# M460 register map
File version: 1.0
Registers are 32-bit, read-write, reset 0x0 unless marked. A register's access mark holds for its fields unless they carry their own. Offsets are from the block's base; [hi:lo] are bit positions; {n}, {i} and the like mark numbered series; 'fields as' and 'values as' point back to an identical list.

## ACMP23 — ACMP Register Map
Base 0x400C9000
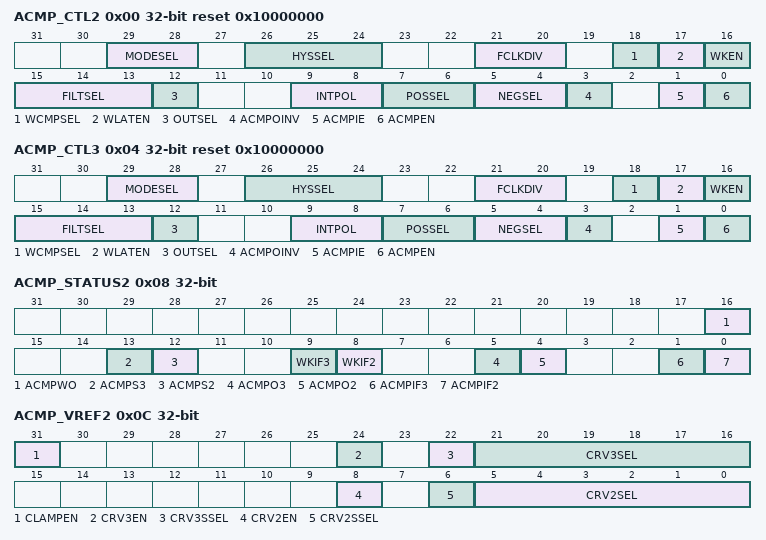
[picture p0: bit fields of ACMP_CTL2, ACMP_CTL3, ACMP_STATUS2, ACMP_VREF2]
0x00 ACMP_CTL2 reset 0x10000000 — Analog Comparator 2 Control Register
  [29:28] MODESEL — Comparator Power Mode Selection. Note: There is a setup time TSetup after comparator is enabled or MODESEL is changed. User should wait this TSetup to make comparator working normally, or user may get unstable comparator output value.
    0=Low power mode comparator AVDD current 1uA; 1=Low power mode comparator AVDD current 2uA; 2=Active mode comparator AVDD current 35uA; 3=Active mode comparator AVDD current 70uA
  [26:24] HYSSEL — Hysteresis Mode Selection
    0=Hysteresis is 0mV; 1=Hysteresis is 10mV; 2=Hysteresis is 20mV; 3=Hysteresis is 30mV; 4=Hysteresis is 40mV; 5=Hysteresis is 50mV
  [21:20] FCLKDIV — Comparator Output Filter Clock Divider
    0=Comparator output filter clock = PCLK; 1=Comparator output filter clock = PCLK/2; 2=Comparator output filter clock = PCLK/4
  [18] WCMPSEL — Window Compare Mode Selection
    0=Window Compare Mode Disabled; 1=Window Compare Mode Selected
  [17] WLATEN — Window Latch Mode Enable Bit
    0=Window Latch Mode Disabled; 1=Window Latch Mode Enabled
  [16] WKEN — Power-down Wake-up Enable Bit
    0=Wake-up function Disabled; 1=Wake-up function Enabled
  [15:13] FILTSEL — Comparator Output Filter Count Selection
    0=Filter function is Disabled; 1=ACMP2 output is sampled 1 consecutive PCLK; 2=ACMP2 output is sampled 2 consecutive PCLKs; 3=ACMP2 output is sampled 4 consecutive PCLKs; 4=ACMP2 output is sampled 8 consecutive PCLKs; 5=ACMP2 output is sampled 16 consecutive PCLKs; 6=ACMP2 output is sampled 32 consecutive PCLKs; 7=ACMP2 output is sampled 64 consecutive PCLKs
  [12] OUTSEL — Comparator Output Select
    0=Comparator 2 output to ACMP2_O pin is unfiltered comparator output; 1=Comparator 2 output to ACMP2_O pin is from filter output
  [9:8] INTPOL — Interrupt Condition Polarity Selection. ACMPIF2 will be set to 1 when comparator output edge condition is detected.
    0=Rising edge or falling edge; 1=Rising edge; 2=Falling edge
  [7:6] POSSEL — Comparator Positive Input Selection
    {v}=Input from ACMP2_P{v} (v=0..3)
  [5:4] NEGSEL — Comparator Negative Input Selection. Note: NEGSEL must select 0x1 in calibration mode.
    0=ACMP2_N pin; 1=Internal comparator reference voltage (CRV2); 2=Band-gap voltage; 3=DAC1 output
  [3] ACMPOINV — Comparator Output Inverse
    0=Comparator 2 output inverse Disabled; 1=Comparator 2 output inverse Enabled
  [1] ACMPIE — Comparator Interrupt Enable Bit
    0=Comparator 2 interrupt Disabled; 1=Comparator 2 interrupt Enabled. If WKEN (ACMP_CTL2[16]) is set to 1, the wake-up interrupt function will be enabled as well
  [0] ACMPEN — Comparator Enable Bit. Note: There is a setup time TSetup after comparator is enabled or MODESEL is changed. User should wait this TSetup to make comparator working normally, or user may get unstable comparator output value.
    0=Comparator 2 Disabled; 1=Comparator 2 Enabled
0x04 ACMP_CTL3 reset 0x10000000 — Analog Comparator 3 Control Register
  [29:28] MODESEL — Comparator Power Mode Selection. Note: There is a setup time TSetup after comparator is enabled or MODESEL is changed. User should wait this TSetup to make comparator working normally, or user may get unstable comparator output value.
    values as ACMP_CTL2.MODESEL
  [26:24] HYSSEL — Hysteresis Mode Selection
    values as ACMP_CTL2.HYSSEL
  [21:20] FCLKDIV — Comparator Output Filter Clock Divider
    values as ACMP_CTL2.FCLKDIV
  [18] WCMPSEL — Window Compare Mode Selection
    values as ACMP_CTL2.WCMPSEL
  [17] WLATEN — Window Latch Mode Enable Bit
    0=Window Latch Mode Disabled; 1=Window Latch Mode Enabled
  [16] WKEN — Power-down Wakeup Enable Bit
    0=Wake-up function Disabled; 1=Wake-up function Enabled
  [15:13] FILTSEL — Comparator Output Filter Count Selection
    0=Filter function is Disabled; 1=ACMP3 output is sampled 1 consecutive PCLK; 2=ACMP3 output is sampled 2 consecutive PCLKs; 3=ACMP3 output is sampled 4 consecutive PCLKs; 4=ACMP3 output is sampled 8 consecutive PCLKs; 5=ACMP3 output is sampled 16 consecutive PCLKs; 6=ACMP3 output is sampled 32 consecutive PCLKs; 7=ACMP3 output is sampled 64 consecutive PCLKs
  [12] OUTSEL — Comparator Output Select
    0=Comparator 3 output to ACMP3_O pin is unfiltered comparator output; 1=Comparator 3 output to ACMP3_O pin is from filter output
  [9:8] INTPOL — Interrupt Condition Polarity Selection. ACMPIF3 will be set to 1 when comparator output edge condition is detected.
    0=Rising edge or falling edge; 1=Rising edge; 2=Falling edge
  [7:6] POSSEL — Comparator Positive Input Selection
    {v}=Input from ACMP3_P{v} (v=0..3)
  [5:4] NEGSEL — Comparator Negative Input Selection. Note: NEGSEL must select 0x1 in calibration mode.
    0=ACMP3_N pin; 1=Internal comparator reference voltage (CRV3); 2=Band-gap voltage; 3=DAC1 output
  [3] ACMPOINV — Comparator Output Inverse Control
    0=Comparator 3 output inverse Disabled; 1=Comparator 3 output inverse Enabled
  [1] ACMPIE — Comparator Interrupt Enable Bit
    0=Comparator 3 interrupt Disabled; 1=Comparator 3 interrupt Enabled. If WKEN (ACMP_CTL1[16]) is set to 1, the wake-up interrupt function will be enabled as well
  [0] ACMPEN — Comparator Enable Bit. Note: There is a setup time TSetup after comparator is enabled or MODESEL is changed. User should wait this TSetup to make comparator working normally, or user may get unstable comparator output value.
    0=Comparator 3 Disabled; 1=Comparator 3 Enabled
0x08 ACMP_STATUS2 — Analog Comparator Status Register 2
  [16] ACMPWO — Comparator Window Output. This bit shows the output status of window compare mode
    0=The positive input voltage is outside the window; 1=The positive input voltage is in the window
  [13] ACMPS3 — Comparator 1 Status. Synchronized to the PCLK to allow reading by software. Cleared when the comparator 3 is disabled, i.e. ACMPEN (ACMP_CTL3[0]) is cleared to 0.
  [12] ACMPS2 — Comparator 2 Status. Synchronized to the PCLK to allow reading by software. Cleared when the comparator 2 is disabled, i.e. ACMPEN (ACMP_CTL2[0]) is cleared to 0.
  [9] WKIF3 — Comparator 3 Power-down Wake-up Interrupt Flag. This bit will be set to 1 when ACMP3 wake-up interrupt event occurs. Note: Write 1 to clear this bit to 0.
    0=No power-down wake-up occurred; 1=Power-down wake-up occurred
  [8] WKIF2 — Comparator 2 Power-down Wake-up Interrupt Flag. This bit will be set to 1 when ACMP2 wake-up interrupt event occurs. Note: Write 1 to clear this bit to 0.
    values as WKIF3
  [5] ACMPO3 — Comparator 3 Output. Synchronized to the PCLK to allow reading by software. Cleared when the comparator 3 is disabled, i.e. ACMPEN (ACMP_CTL3[0]) is cleared to 0.
  [4] ACMPO2 — Comparator 2 Output. Synchronized to the PCLK to allow reading by software. Cleared when the comparator 2 is disabled, i.e. ACMPEN (ACMP_CTL2[0]) is cleared to 0.
  [1] ACMPIF3 — Comparator 3 Interrupt Flag. This bit is set by hardware when the edge condition defined by INTPOL (ACMP_CTL3[9:8]) is detected on comparator 3 output. This will cause an interrupt if ACMPIE (ACMP_CTL3[1]) is set to 1. Note: Write 1 to clear this bit to 0.
  [0] ACMPIF2 — Comparator 2 Interrupt Flag. This bit is set by hardware when the edge condition defined by INTPOL (ACMP_CTL2[9:8]) is detected on comparator 2 output. This will generate an interrupt if ACMPIE (ACMP_CTL2[1]) is set to 1. Note: Write 1 to clear this bit to 0.
0x0C ACMP_VREF2 — Analog Comparator Reference Voltage Control Register 2
  [31] CLAMPEN — Current Level Control Selection under Speed Up Function
    0=ACMP run on high SPEED mode with high quiescent current; 1=ACMP run on low SPEED mode with high quiescent current
  [24] CRV3EN — CRV3 Enable Bit
    0=CRV3 Disabled; 1=CRV3 Enabled
  [22] CRV3SSEL — CRV3 Source Voltage Selection
    0=AVDD is selected as CRV3 source voltage; 1=The reference voltage defined by SYS_VREFCTL register is selected as CRV3 source voltage
  [21:16] CRV3SEL — Comparator3 Reference Voltage Setting
  [8] CRV2EN — CRV2 Enable Bit
    0=CRV2 Disabled; 1=CRV2 Enabled
  [6] CRV2SSEL — CRV2 Source Voltage Selection
    0=AVDD is selected as CRV2 source voltage; 1=The reference voltage defined by SYS_VREFCTL register is selected as CRV2 source voltage
  [5:0] CRV2SEL — Comparator2 Reference Voltage Setting
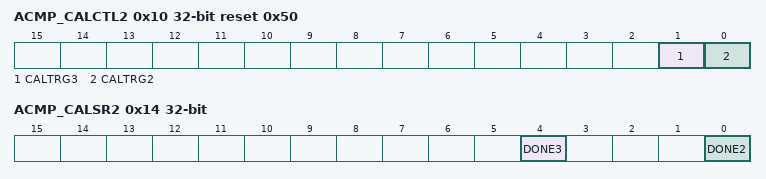
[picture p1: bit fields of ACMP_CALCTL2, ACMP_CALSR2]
0x10 ACMP_CALCTL2 reset 0x50 — Analog Comparator Calibration Control Register 2
  [1] CALTRG3 — Comparator3 Calibration Trigger Bit. Note 1: Before this bit is enabled, ACMPEN(ACMP_CTL3[0]) should be set and the internal high speed RC oscillator (HIRC) should be enabled in advance. Note 2: Hardware will automatically clear this bit when the next calibration is triggered by software. Note 3: If user must trigger calibration twice or more times, the second trigger has to wait at least 300us after the previous calibration is done.
    0=Calibration is stopped; 1=Calibration is triggered
  [0] CALTRG2 — Comparator2 Calibration Trigger Bit. Note 1: Before this bit is enabled, ACMPEN(ACMP_CTL2[0]) should be set and the internal high speed RC oscillator (HIRC) should be enabled in advance. Note 2: Hardware will automatically clear this bit when the next calibration is triggered by software. Note 3: If user must trigger calibration twice or more times, the second trigger has to wait at least 300us after the previous calibration is done.
    0=Calibration is stopped; 1=Calibration is triggered
0x14 ACMP_CALSR2 ro — Analog Comparator Calibration Status Register 2
  [4] DONE3 — Comparator3 Calibration Done Status. Note: Write 1 to clear this bit to 0.
    0=Calibrating; 1=Calibration done
  [0] DONE2 — Comparator2 Calibration Done Status. Note: Write 1 to clear this bit to 0.
    0=Calibrating; 1=Calibration done
